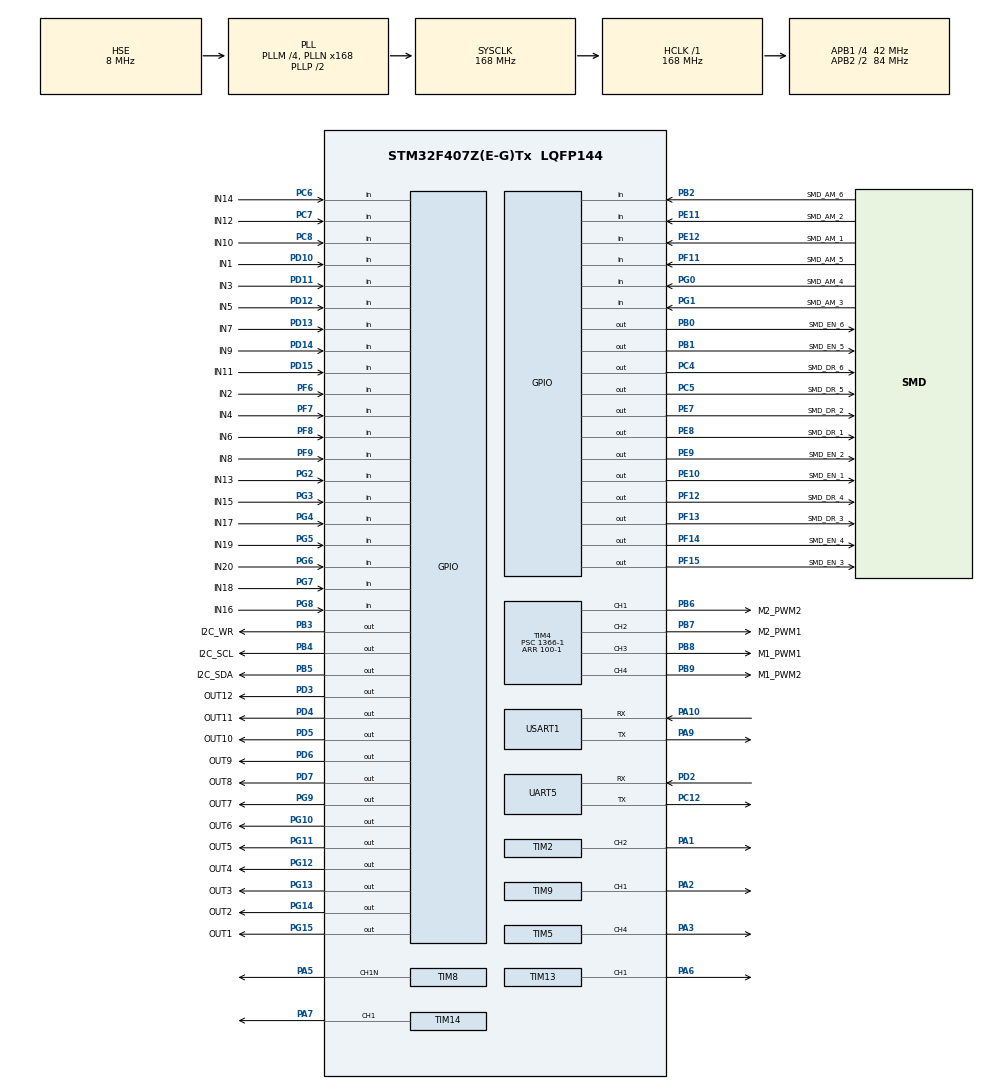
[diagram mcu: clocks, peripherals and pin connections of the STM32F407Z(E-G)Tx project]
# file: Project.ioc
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Mcu.Family=STM32F4
Mcu.Name=STM32F407Z(E-G)Tx
Mcu.Package=LQFP144
NVIC.PriorityGroup=NVIC_PRIORITYGROUP_4
NVIC.TIM1_TRG_COM_TIM11_IRQn=true\:0\:0\:false\:false\:true\:true\:true\:true
NVIC.TIM1_UP_TIM10_IRQn=true\:0\:0\:false\:false\:false\:true\:true\:true
NVIC.TIM6_DAC_IRQn=true\:0\:0\:false\:false\:false\:true\:true\:true
NVIC.TIM7_IRQn=true\:0\:0\:false\:false\:false\:true\:true\:true
NVIC.UART5_IRQn=true\:0\:0\:false\:false\:false\:true\:true\:true
NVIC.USART1_IRQn=true\:0\:0\:false\:false\:false\:true\:true\:true
PA1.Signal=S_TIM2_CH2
PA10.Mode=Asynchronous
PA10.Signal=USART1_RX
PA13.Mode=Serial_Wire
PA13.Signal=SYS_JTMS-SWDIO
PA14.Mode=Serial_Wire
PA14.Signal=SYS_JTCK-SWCLK
PA2.Signal=S_TIM9_CH1
PA3.Signal=S_TIM5_CH4
PA5.Mode=PWM Generation1 CH1N
PA5.Signal=TIM8_CH1N
PA6.Signal=S_TIM13_CH1
PA7.Signal=S_TIM14_CH1
PA9.Mode=Asynchronous
PA9.Signal=USART1_TX
PB0.GPIO_Label=SMD_EN_6
PB0.Signal=GPIO_Output
PB1.GPIO_Label=SMD_EN_5
PB1.Signal=GPIO_Output
PB2.GPIO_Label=SMD_AM_6
PB2.GPIO_PuPd=GPIO_PULLUP
PB2.Signal=GPIO_Input
PB3.GPIO_Label=I2C_WR
PB3.Signal=GPIO_Output
PB4.GPIO_Label=I2C_SCL
PB4.GPIO_ModeDefaultOutputPP=GPIO_MODE_OUTPUT_OD
PB4.GPIO_PuPd=GPIO_NOPULL
PB4.Signal=GPIO_Output
PB5.GPIO_Label=I2C_SDA
PB5.GPIO_ModeDefaultOutputPP=GPIO_MODE_OUTPUT_OD
PB5.GPIO_PuPd=GPIO_NOPULL
PB5.Signal=GPIO_Output
PB6.GPIO_Label=M2_PWM2
PB6.Signal=S_TIM4_CH1
PB7.GPIO_Label=M2_PWM1
PB7.Signal=S_TIM4_CH2
PB8.GPIO_Label=M1_PWM1
PB8.Signal=S_TIM4_CH3
PB9.GPIO_Label=M1_PWM2
PB9.Signal=S_TIM4_CH4
PC12.Mode=Asynchronous
PC12.Signal=UART5_TX
PC4.GPIO_Label=SMD_DR_6
PC4.Signal=GPIO_Output
PC5.GPIO_Label=SMD_DR_5
PC5.Signal=GPIO_Output
PC6.GPIO_Label=IN14
PC6.GPIO_PuPd=GPIO_PULLUP
PC6.Signal=GPIO_Input
PC7.GPIO_Label=IN12
PC7.GPIO_PuPd=GPIO_PULLUP
PC7.Signal=GPIO_Input
PC8.GPIO_Label=IN10
PC8.GPIO_PuPd=GPIO_PULLUP
PC8.Signal=GPIO_Input
PD10.GPIO_Label=IN1
PD10.GPIO_PuPd=GPIO_PULLUP
PD10.Signal=GPIO_Input
PD11.GPIO_Label=IN3
PD11.GPIO_PuPd=GPIO_PULLUP
PD11.Signal=GPIO_Input
PD12.GPIO_Label=IN5
PD12.GPIO_PuPd=GPIO_PULLUP
PD12.Signal=GPIO_Input
PD13.GPIO_Label=IN7
PD13.GPIO_PuPd=GPIO_PULLUP
PD13.Signal=GPIO_Input
PD14.GPIO_Label=IN9
PD14.GPIO_PuPd=GPIO_PULLUP
PD14.Signal=GPIO_Input
PD15.GPIO_Label=IN11
PD15.GPIO_PuPd=GPIO_PULLUP
PD15.Signal=GPIO_Input
PD2.Mode=Asynchronous
PD2.Signal=UART5_RX
PD3.GPIO_Label=OUT12
PD3.Signal=GPIO_Output
PD4.GPIO_Label=OUT11
PD4.Signal=GPIO_Output
PD5.GPIO_Label=OUT10
PD5.Signal=GPIO_Output
PD6.GPIO_Label=OUT9
PD6.Signal=GPIO_Output
PD7.GPIO_Label=OUT8
PD7.Signal=GPIO_Output
PE10.GPIO_Label=SMD_EN_1
PE10.Signal=GPIO_Output
PE11.GPIO_Label=SMD_AM_2
PE11.GPIO_PuPd=GPIO_PULLUP
PE11.Signal=GPIO_Input
PE12.GPIO_Label=SMD_AM_1
PE12.GPIO_PuPd=GPIO_PULLUP
PE12.Signal=GPIO_Input
PE7.GPIO_Label=SMD_DR_2
PE7.Signal=GPIO_Output
PE8.GPIO_Label=SMD_DR_1
PE8.Signal=GPIO_Output
PE9.GPIO_Label=SMD_EN_2
PE9.Signal=GPIO_Output
PF11.GPIO_Label=SMD_AM_5
PF11.GPIO_PuPd=GPIO_PULLUP
PF11.Signal=GPIO_Input
PF12.GPIO_Label=SMD_DR_4
PF12.Signal=GPIO_Output
PF13.GPIO_Label=SMD_DR_3
PF13.Signal=GPIO_Output
PF14.GPIO_Label=SMD_EN_4
PF14.Signal=GPIO_Output
PF15.GPIO_Label=SMD_EN_3
PF15.Signal=GPIO_Output
PF6.GPIO_Label=IN2
PF6.GPIO_PuPd=GPIO_PULLUP
PF6.Signal=GPIO_Input
PF7.GPIO_Label=IN4
PF7.GPIO_PuPd=GPIO_PULLUP
PF7.Signal=GPIO_Input
PF8.GPIO_Label=IN6
PF8.GPIO_PuPd=GPIO_PULLUP
PF8.Signal=GPIO_Input
PF9.GPIO_Label=IN8
PF9.GPIO_PuPd=GPIO_PULLUP
PF9.Signal=GPIO_Input
PG0.GPIO_Label=SMD_AM_4
PG0.GPIO_PuPd=GPIO_PULLUP
PG0.Signal=GPIO_Input
PG1.GPIO_Label=SMD_AM_3
PG1.GPIO_PuPd=GPIO_PULLUP
PG1.Signal=GPIO_Input
PG10.GPIO_Label=OUT6
PG10.Signal=GPIO_Output
PG11.GPIO_Label=OUT5
PG11.Signal=GPIO_Output
PG12.GPIO_Label=OUT4
PG12.Signal=GPIO_Output
PG13.GPIO_Label=OUT3
PG13.Signal=GPIO_Output
PG14.GPIO_Label=OUT2
PG14.Signal=GPIO_Output
PG15.GPIO_Label=OUT1
PG15.Signal=GPIO_Output
PG2.GPIO_Label=IN13
PG2.GPIO_PuPd=GPIO_PULLUP
PG2.Signal=GPIO_Input
PG3.GPIO_Label=IN15
PG3.GPIO_PuPd=GPIO_PULLUP
PG3.Signal=GPIO_Input
PG4.GPIO_Label=IN17
PG4.GPIO_PuPd=GPIO_PULLUP
PG4.Signal=GPIO_Input
PG5.GPIO_Label=IN19
PG5.GPIO_PuPd=GPIO_PULLUP
PG5.Signal=GPIO_Input
PG6.GPIO_Label=IN20
PG6.GPIO_PuPd=GPIO_PULLUP
PG6.Signal=GPIO_Input
PG7.GPIO_Label=IN18
PG7.GPIO_PuPd=GPIO_PULLUP
PG7.Signal=GPIO_Input
PG8.GPIO_Label=IN16
PG8.GPIO_PuPd=GPIO_PULLUP
PG8.Signal=GPIO_Input
PG9.GPIO_Label=OUT7
PG9.Signal=GPIO_Output
PH0-OSC_IN.Mode=HSE-External-Oscillator
PH0-OSC_IN.Signal=RCC_OSC_IN
PH1-OSC_OUT.Mode=HSE-External-Oscillator
PH1-OSC_OUT.Signal=RCC_OSC_OUT
ProjectManager.HeapSize=0x200
ProjectManager.StackSize=0x400
ProjectManager.TargetToolchain=MDK-ARM V5.32
RCC.48MHZClocksFreq_Value=84000000
RCC.AHBFreq_Value=168000000
RCC.APB1CLKDivider=RCC_HCLK_DIV4
RCC.APB1Freq_Value=42000000
RCC.APB1TimFreq_Value=84000000
RCC.APB2CLKDivider=RCC_HCLK_DIV2
RCC.APB2Freq_Value=84000000
RCC.APB2TimFreq_Value=168000000
RCC.CortexFreq_Value=168000000
RCC.HCLKFreq_Value=168000000
RCC.HSE_VALUE=8000000
RCC.HSI_VALUE=16000000
RCC.LSE_VALUE=32768
RCC.PLLM=4
RCC.PLLN=168
RCC.PLLSourceVirtual=RCC_PLLSOURCE_HSE
RCC.SYSCLKFreq_VALUE=168000000
RCC.SYSCLKSource=RCC_SYSCLKSOURCE_PLLCLK
RCC.VCOOutputFreq_Value=336000000
SH.S_TIM13_CH1.0=TIM13_CH1,PWM Generation1 CH1
SH.S_TIM14_CH1.0=TIM14_CH1,PWM Generation1 CH1
SH.S_TIM2_CH2.0=TIM2_CH2,PWM Generation2 CH2
SH.S_TIM4_CH1.0=TIM4_CH1,PWM Generation1 CH1
SH.S_TIM4_CH2.0=TIM4_CH2,PWM Generation2 CH2
SH.S_TIM4_CH3.0=TIM4_CH3,PWM Generation3 CH3
SH.S_TIM4_CH4.0=TIM4_CH4,PWM Generation4 CH4
SH.S_TIM5_CH4.0=TIM5_CH4,PWM Generation4 CH4
SH.S_TIM9_CH1.0=TIM9_CH1,PWM Generation1 CH1
TIM10.Period=1000-1
TIM10.Prescaler=168-1
TIM11.Period=100-1
TIM11.Prescaler=168-1
TIM13.Channel=TIM_CHANNEL_1
TIM14.Channel=TIM_CHANNEL_1
TIM2.Channel-PWM\ Generation2\ CH2=TIM_CHANNEL_2
TIM4.Channel-PWM\ Generation1\ CH1=TIM_CHANNEL_1
TIM4.Channel-PWM\ Generation2\ CH2=TIM_CHANNEL_2
TIM4.Channel-PWM\ Generation3\ CH3=TIM_CHANNEL_3
TIM4.Channel-PWM\ Generation4\ CH4=TIM_CHANNEL_4
TIM4.Period=100-1
TIM4.Prescaler=1366-1
TIM5.Channel-PWM\ Generation4\ CH4=TIM_CHANNEL_4
TIM8.Channel-PWM\ Generation1\ CH1N=TIM_CHANNEL_1
TIM9.Channel-PWM\ Generation1\ CH1=TIM_CHANNEL_1
UART5.VirtualMode=Asynchronous
USART1.VirtualMode=VM_ASYNC
VP_TIM10_VS_ClockSourceINT.Mode=Enable_Timer
VP_TIM11_VS_ClockSourceINT.Mode=Enable_Timer
VP_TIM13_VS_ClockSourceINT.Mode=Enable_Timer
VP_TIM14_VS_ClockSourceINT.Mode=Enable_Timer
VP_TIM6_VS_ClockSourceINT.Mode=Enable_Timer
VP_TIM7_VS_ClockSourceINT.Mode=Enable_Timer
board=custom

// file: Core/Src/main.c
/* USER CODE BEGIN Header */
/**
  ******************************************************************************
  * @file           : main.c
  * @brief          : Main program body
  ******************************************************************************
  * @attention
  *
  * Copyright (c) 2026 STMicroelectronics.
  * All rights reserved.
  *
  * This software is licensed under terms that can be found in the LICENSE file
  * in the root directory of this software component.
  * If no LICENSE file comes with this software, it is provided AS-IS.
  *
  ******************************************************************************
  */
/* USER CODE END Header */
#include "main.h"
#include "tim.h"
#include "usart.h"
#include "gpio.h"

/* USER CODE BEGIN Includes */
#include "mb_host.h"
#include "mb_slave.h"
#include "api_delay.h"
#include "api_timer.h"
#include "api_smd.h"
#include "api_motor_control.h"
#include "api_eeprom.h"
#include "mb_hook.h"
#include "mb_fwupd.h"
/* USER CODE END Includes */

/* USER CODE BEGIN PV */
uint32_t Cnt = 0;
extern uint32_t __Vectors[];   /* startup_stm32f407xx.s 的向量表（链接在 0x08010000，前面是 bootloader） */
/* USER CODE END PV */

void SystemClock_Config(void);

int main(void)
{

    /* USER CODE BEGIN 1 */
    /* 程序由 bootloader 跳转进来时 bootloader 已设好 VTOR；用 ST-Link 直接下载调试时复位后
     * 先跑 bootloader 再跳过来，同样如此。这里按链接出来的向量表地址再设一次，不依赖调用方 */
    SCB->VTOR = (uint32_t)__Vectors;
    /* USER CODE END 1 */

    /* MCU Configuration--------------------------------------------------------*/

    /* Reset of all peripherals, Initializes the Flash interface and the Systick. */
    HAL_Init();

    /* Configure the system clock */
    SystemClock_Config();

    /* Initialize all configured peripherals */
    MX_GPIO_Init();
    MX_TIM6_Init();
    MX_TIM7_Init();
    MX_UART5_Init();
    MX_USART1_UART_Init();
    MX_TIM2_Init();
    MX_TIM4_Init();
    MX_TIM5_Init();
    MX_TIM13_Init();
    MX_TIM8_Init();
    MX_TIM9_Init();
    MX_TIM10_Init();
    MX_TIM11_Init();
    MX_TIM14_Init();
    /* USER CODE BEGIN 2 */
    /* 修复S曲线抖动：CubeMX生成的定时器初始化默认关闭ARR预装载（ARPE=0），
     * 而 api_smd.c 的 SMD_ApplyFreqToHW() 每1ms在周期中途写ARR，依赖ARPE=1
     * 保证修改在下一个更新事件生效（无毛刺）。ARPE=0时，加减速阶段新ARR
     * 小于当前CNT会使16位定时器一路计到0xFFFF才回绕（最长约65ms的拉长脉冲），
     * 导致步数控制模式下电机抖动、且停不到目标位置。
     * 这里把6路步进PWM定时器按ARPE=1重新初始化（旧板smd.c即如此）。
     * 注意：必须改Init字段并重调HAL_TIM_PWM_Init，因为SMD_PWM_SetFreq()
     * 内部会再次调用HAL_TIM_PWM_Init，按Init字段把ARPE写回寄存器。
     *
     * 同时把 Init.Period 写为 19999（20ms 占位周期）：CubeMX 给 32 位定时器
     * （TIM2/TIM5）生成的 ARR=0xFFFFFFFF 若残留在影子寄存器里，ARPE=1 下
     * 运行中写入的新 ARR 要等计数器溢出（1MHz 计数 ≈71 分钟）才出现第一个
     * 更新事件——期间 PWM 引脚无脉冲（表现为开机后电机延迟执行、S曲线/步数
     * 计数空跑）。HAL_TIM_PWM_Init 内部会生成更新事件把占位周期立即锁入
     * 影子寄存器，此后任何一次启动最迟 20ms 内生效。配合 api_smd.c 的
     * SMD_Calc_PSC_ARR 最低 50Hz 钳位，运行时不再需要生成更新事件。 */
    htim2.Init.AutoReloadPreload  = TIM_AUTORELOAD_PRELOAD_ENABLE; htim2.Init.Period  = 19999; HAL_TIM_PWM_Init(&htim2);
    htim5.Init.AutoReloadPreload  = TIM_AUTORELOAD_PRELOAD_ENABLE; htim5.Init.Period  = 19999; HAL_TIM_PWM_Init(&htim5);
    htim8.Init.AutoReloadPreload  = TIM_AUTORELOAD_PRELOAD_ENABLE; htim8.Init.Period  = 19999; HAL_TIM_PWM_Init(&htim8);
    htim9.Init.AutoReloadPreload  = TIM_AUTORELOAD_PRELOAD_ENABLE; htim9.Init.Period  = 19999; HAL_TIM_PWM_Init(&htim9);
    htim13.Init.AutoReloadPreload = TIM_AUTORELOAD_PRELOAD_ENABLE; htim13.Init.Period = 19999; HAL_TIM_PWM_Init(&htim13);
    htim14.Init.AutoReloadPreload = TIM_AUTORELOAD_PRELOAD_ENABLE; htim14.Init.Period = 19999; HAL_TIM_PWM_Init(&htim14);
    Delay_Init();
    EEPROM_Init();
    SMD_Belt_Init();   /* 排发皮带一圈步数（EEPROM）+ ch4 初始电平 */
    mbh_init(&mbhMCU);
    mbs_init(&mbsUSB);
    fwu_init(FWU_MODE_APP, g_fwuInfo.ver_major, g_fwuInfo.ver_minor, g_fwuInfo.ver_patch);
    API_MOTOR_Init(&htim4, 5000);
#if M6TOSERVO_ENABLE
    /* 舵机初始化：TIM2_CH2 配 50Hz 基时，从EEPROM载入参数
     * （全0/全0xFF时写默认角度 120/120/50；行程时长不存EEPROM，开机默认5500ms），并按初始角度直接
     * 输出 PWM；DR6 拉低作舵机地线（EN6 已硬件飞线接地） */
    SMD_Servo_Init();
#endif
    for (int ch = 0; ch < SMD_CH_MAX; ch++)
    {
#if M6TOSERVO_ENABLE
        if (ch == SERVO_CH) continue;  /* 舵机通道：跳过步进S曲线启动 */
#endif
        SMD_PWM_SetFreqGradient((SMD_Channel)ch, SMD_PU_DATA[ch], SMD_ACC_DATA[ch]);
    }

    /* 开机找零：排发皮带以 BELT_ZERO_FREQ 转到 ch4 黑点（零点当场锁存）后减速停，137 皮带进度随即有效 */
    SMD_Belt_SeekZeroStart();

    SMD_GripperCounterInit();
    HAL_TIM_Base_Start_IT(&htim10);
    HAL_TIM_Base_Start_IT(&htim11);
    /* USER CODE END 2 */

    /* Infinite loop */
    /* USER CODE BEGIN WHILE */
    while (1)
    {

        if (bsp_timer_IsFlagSet(BSP_TIMER_FLAG_10MS))
        {
            bsp_timer_ClearFlag(BSP_TIMER_FLAG_10MS);

            uint8_t data[] = {0, 1, 0, 10};
            mbh_send(&mbhMCU, 1, 3, data, 4);

            /* 更新电机速度（非阻塞式）：由100ms周期改为10ms，配合默认2%步进，
             * 0->100%加减速时间从5秒缩短到0.5秒 */
            API_MOTOR_UpdateSpeed();
        }

        /* USER CODE END WHILE */

        /* USER CODE BEGIN 3 */
        mbh_poll(&mbhMCU);
        mbs_poll(&mbsUSB);
        SMD_Belt_SaveIfPending();   /* 皮带 EEPROM 写入：标定一圈步数/圈计数纪元/停稳位置记录（I2C 不放在中断里） */

        /* 上位机升级命令 REBOOT/ENTER_BOOT：应答发出后复位，由 bootloader 安装新固件或停在升级模式 */
        if (fwu_poll(HAL_GetTick()))
            NVIC_SystemReset();
    }

    /* USER CODE END 3 */
}

void SystemClock_Config(void)
{
    RCC_OscInitTypeDef RCC_OscInitStruct = {0};
    RCC_ClkInitTypeDef RCC_ClkInitStruct = {0};

    /** Configure the main internal regulator output voltage
    */
    __HAL_RCC_PWR_CLK_ENABLE();
    __HAL_PWR_VOLTAGESCALING_CONFIG(PWR_REGULATOR_VOLTAGE_SCALE1);

    /** Initializes the RCC Oscillators according to the specified parameters
    * in the RCC_OscInitTypeDef structure.
    */
    RCC_OscInitStruct.OscillatorType = RCC_OSCILLATORTYPE_HSE;
    RCC_OscInitStruct.HSEState = RCC_HSE_ON;
    RCC_OscInitStruct.PLL.PLLState = RCC_PLL_ON;
    RCC_OscInitStruct.PLL.PLLSource = RCC_PLLSOURCE_HSE;
    RCC_OscInitStruct.PLL.PLLM = 4;
    RCC_OscInitStruct.PLL.PLLN = 168;
    RCC_OscInitStruct.PLL.PLLP = RCC_PLLP_DIV2;
    RCC_OscInitStruct.PLL.PLLQ = 4;

    if (HAL_RCC_OscConfig(&RCC_OscInitStruct) != HAL_OK)
    {
        Error_Handler();
    }

    /** Initializes the CPU, AHB and APB buses clocks
    */
    RCC_ClkInitStruct.ClockType = RCC_CLOCKTYPE_HCLK | RCC_CLOCKTYPE_SYSCLK
                                  | RCC_CLOCKTYPE_PCLK1 | RCC_CLOCKTYPE_PCLK2;
    RCC_ClkInitStruct.SYSCLKSource = RCC_SYSCLKSOURCE_PLLCLK;
    RCC_ClkInitStruct.AHBCLKDivider = RCC_SYSCLK_DIV1;
    RCC_ClkInitStruct.APB1CLKDivider = RCC_HCLK_DIV4;
    RCC_ClkInitStruct.APB2CLKDivider = RCC_HCLK_DIV2;

    if (HAL_RCC_ClockConfig(&RCC_ClkInitStruct, FLASH_LATENCY_5) != HAL_OK)
    {
        Error_Handler();
    }
}

void Error_Handler(void)
{
    __disable_irq();
    while (1)
    {
    }
}
